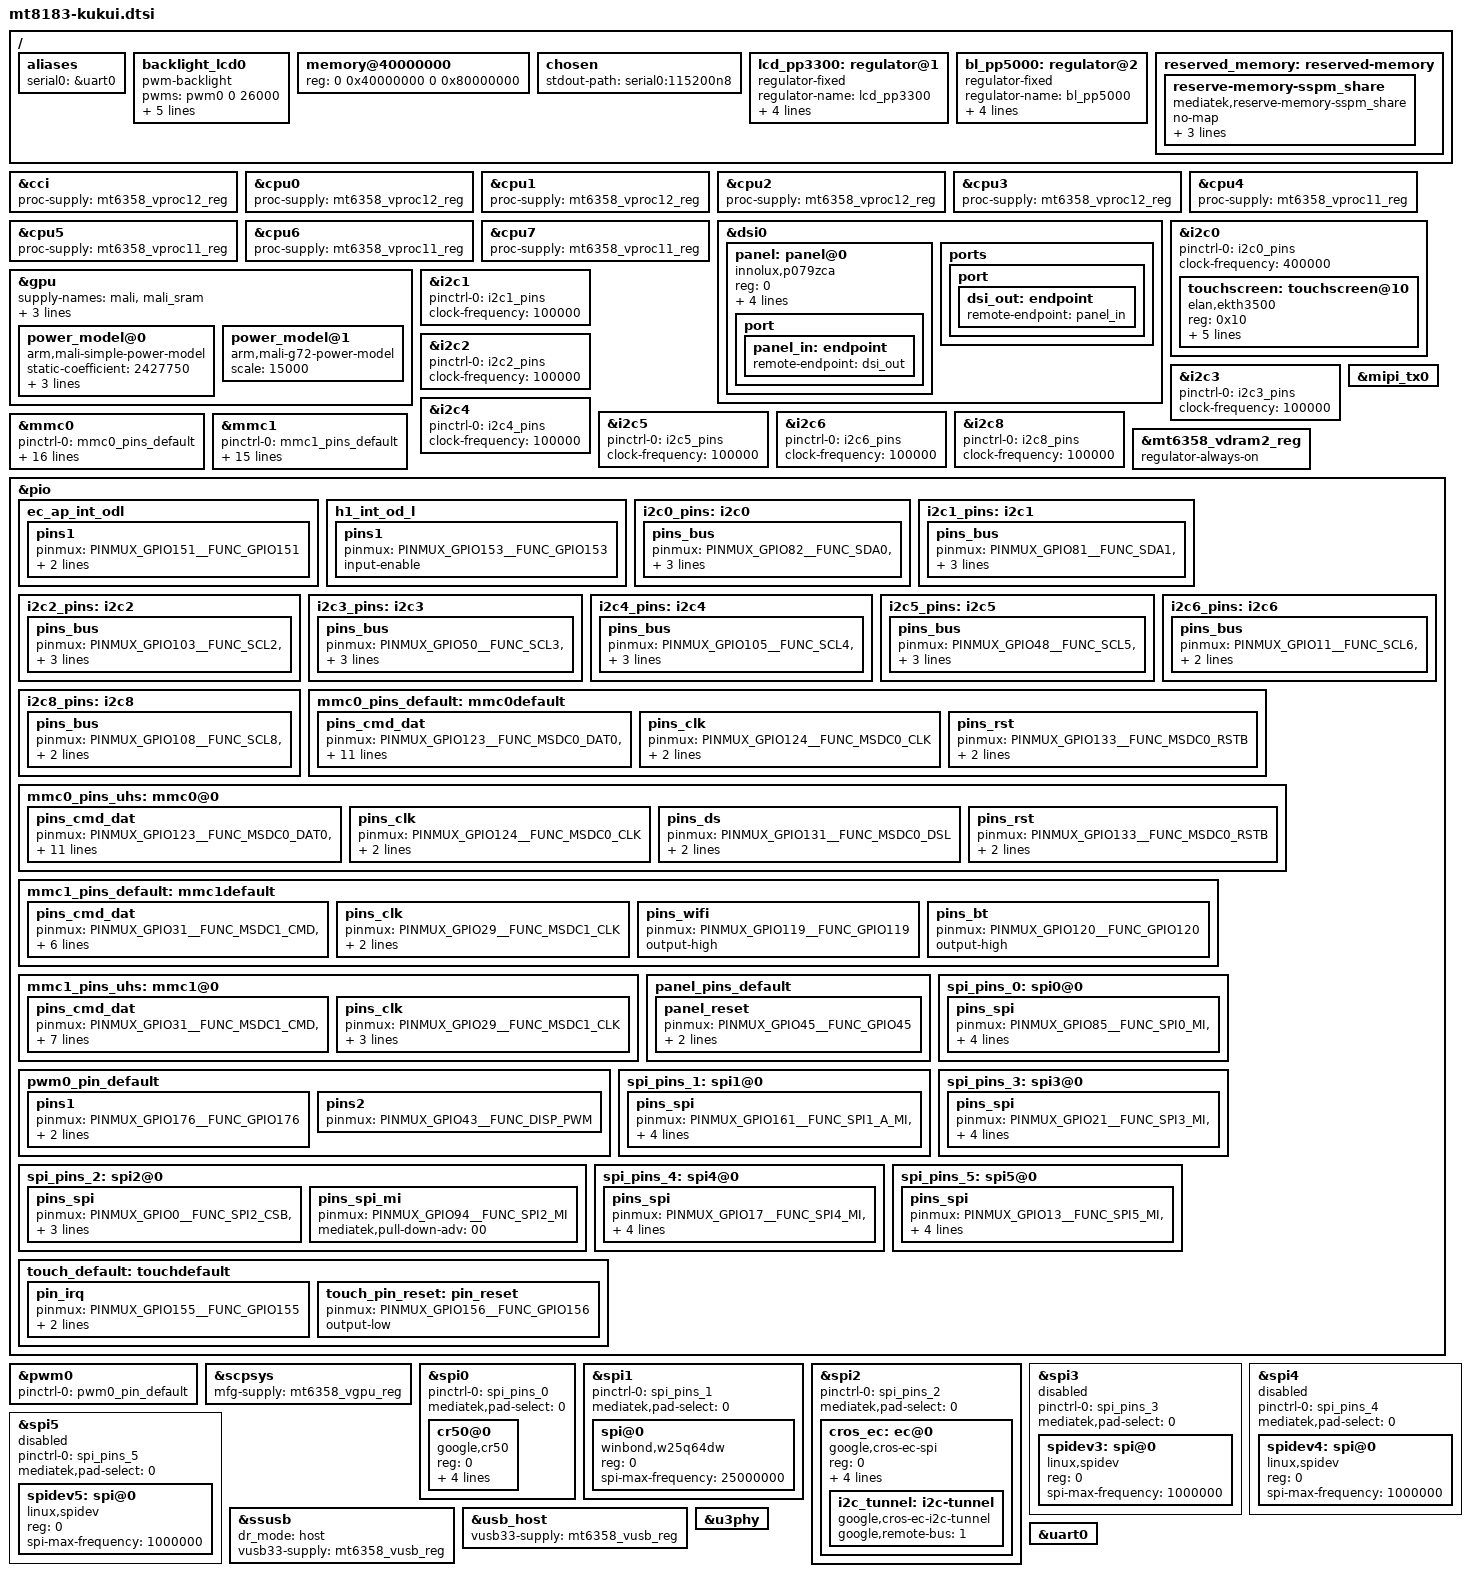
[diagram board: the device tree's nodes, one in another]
// SPDX-License-Identifier: (GPL-2.0 OR MIT)
/*
 * Copyright (c) 2018 MediaTek Inc.
 * Author: Ben Ho <ben.ho@mediatek.com>
 *	   Erin Lo <erin.lo@mediatek.com>
 */

#include <dt-bindings/gpio/gpio.h>
#include "mt8183.dtsi"
#include "mt6358.dtsi"

/ {
	aliases {
		serial0 = &uart0;
	};

	backlight_lcd0: backlight_lcd0 {
		compatible = "pwm-backlight";
		pwms = <&pwm0 0 26000>;
		power-supply = <&bl_pp5000>;
		enable-gpios = <&pio 176 0>;
		brightness-levels = <
			0 64 128 192 256 320 384 448
			512 576 640 704 768 832 896 960
			1023>;
		default-brightness-level = <9>;
		status = "okay";
	};

	memory@40000000 {
		device_type = "memory";
		reg = <0 0x40000000 0 0x80000000>;
	};

	chosen {
		stdout-path = "serial0:115200n8";
	};

	lcd_pp3300: regulator@1 {
		compatible = "regulator-fixed";
		regulator-name = "lcd_pp3300";
		regulator-min-microvolt = <3300000>;
		regulator-max-microvolt = <3300000>;
		regulator-always-on;
		regulator-boot-on;
	};

	bl_pp5000: regulator@2 {
		compatible = "regulator-fixed";
		regulator-name = "bl_pp5000";
		regulator-min-microvolt = <5000000>;
		regulator-max-microvolt = <5000000>;
		regulator-always-on;
		regulator-boot-on;
	};

	reserved_memory: reserved-memory {
		#address-cells = <2>;
		#size-cells = <2>;
		ranges;

		reserve-memory-sspm_share {
			compatible = "mediatek,reserve-memory-sspm_share";
			no-map;
			status = "okay";
			size = <0 0x110000>; /* 1M + 64K */
			alignment = <0 0x10000>;
			alloc-ranges = <0 0x40000000 0 0x60000000>;
		};
	};
};

&cci {
	proc-supply = <&mt6358_vproc12_reg>;
};

&cpu0 {
	proc-supply = <&mt6358_vproc12_reg>;
};

&cpu1 {
	proc-supply = <&mt6358_vproc12_reg>;
};

&cpu2 {
	proc-supply = <&mt6358_vproc12_reg>;
};

&cpu3 {
	proc-supply = <&mt6358_vproc12_reg>;
};

&cpu4 {
	proc-supply = <&mt6358_vproc11_reg>;
};

&cpu5 {
	proc-supply = <&mt6358_vproc11_reg>;
};

&cpu6 {
	proc-supply = <&mt6358_vproc11_reg>;
};

&cpu7 {
	proc-supply = <&mt6358_vproc11_reg>;
};

&dsi0 {
	status = "okay";
	#address-cells = <1>;
	#size-cells = <0>;
	panel: panel@0 {
		compatible = "innolux,p079zca";
		reg = <0>;
		enable-gpios = <&pio 45 0>;
		pinctrl-names = "default";
		pinctrl-0 = <&panel_pins_default>;
		power-supply = <&lcd_pp3300>;
		backlight = <&backlight_lcd0>;
		status = "okay";
		port {
			panel_in: endpoint {
				remote-endpoint = <&dsi_out>;
			};
		};
	};

	ports {
		port {
			dsi_out: endpoint {
				remote-endpoint = <&panel_in>;
			};
		};
	};
};

&gpu {
	supply-names = "mali","mali_sram";
	mali-supply = <&mt6358_vgpu_reg>;
	mali_sram-supply = <&mt6358_vsram_gpu_reg>;
	operating-points-v2 = <&gpu_opp_table>;
	power_model@0 {
		compatible = "arm,mali-simple-power-model";
		static-coefficient = <2427750>;
		dynamic-coefficient = <4687>;
		ts = <20000 2000 (-20) 2>;
		thermal-zone = "cpu_thermal";
	};
	power_model@1 {
		compatible = "arm,mali-g72-power-model";
		scale = <15000>;
	};
};

&i2c0 {
	pinctrl-names = "default";
	pinctrl-0 = <&i2c0_pins>;
	status = "okay";
	clock-frequency = <400000>;
	#address-cells = <1>;
	#size-cells = <0>;

	touchscreen: touchscreen@10 {
		compatible = "elan,ekth3500";
		reg = <0x10>;
		interrupt-parent = <&pio>;
		interrupts = <155 IRQ_TYPE_LEVEL_LOW>;
		int-gpio = <&pio 155 0>;
		pinctrl-names = "default";
		pinctrl-0 = <&touch_default>;

		reset-gpios = <&pio 156 1>;
	};
};

&i2c1 {
	pinctrl-names = "default";
	pinctrl-0 = <&i2c1_pins>;
	status = "okay";
	clock-frequency = <100000>;
};

&i2c2 {
	pinctrl-names = "default";
	pinctrl-0 = <&i2c2_pins>;
	status = "okay";
	clock-frequency = <100000>;
};

&i2c3 {
	pinctrl-names = "default";
	pinctrl-0 = <&i2c3_pins>;
	status = "okay";
	clock-frequency = <100000>;
};

&i2c4 {
	pinctrl-names = "default";
	pinctrl-0 = <&i2c4_pins>;
	status = "okay";
	clock-frequency = <100000>;
};

&i2c5 {
	pinctrl-names = "default";
	pinctrl-0 = <&i2c5_pins>;
	status = "okay";
	clock-frequency = <100000>;
};

&i2c6 {
	pinctrl-names = "default";
	pinctrl-0 = <&i2c6_pins>;
	status = "okay";
	clock-frequency = <100000>;
};

&i2c8 {
	pinctrl-names = "default";
	pinctrl-0 = <&i2c8_pins>;
	status = "okay";
	clock-frequency = <100000>;
};

&mipi_tx0 {
	status = "okay";
};

&mmc0 {
	status = "okay";
	pinctrl-names = "default", "state_uhs";
	pinctrl-0 = <&mmc0_pins_default>;
	pinctrl-1 = <&mmc0_pins_uhs>;
	bus-width = <8>;
	max-frequency = <200000000>;
	cap-mmc-highspeed;
	mmc-hs200-1_8v;
	mmc-hs400-1_8v;
	cap-mmc-hw-reset;
	no-sdio;
	no-sd;
	hs400-ds-delay = <0x13813>;
	vmmc-supply = <&mt6358_vemc_reg>;
	vqmmc-supply = <&mt6358_vio18_reg>;
	assigned-clocks = <&topckgen CLK_TOP_MUX_MSDC50_0>;
	assigned-clock-parents = <&topckgen CLK_TOP_MSDCPLL_CK>;
	non-removable;
};

&mmc1 {
	status = "okay";
	pinctrl-names = "default", "state_uhs";
	pinctrl-0 = <&mmc1_pins_default>;
	pinctrl-1 = <&mmc1_pins_uhs>;
	vmmc-supply = <&mt6358_vmch_reg>;
	vqmmc-supply = <&mt6358_vmc_reg>;
	bus-width = <4>;
	max-frequency = <200000000>;
	drv-type = <2>;
	cap-sd-highspeed;
	sd-uhs-sdr50;
	sd-uhs-sdr104;
	keep-power-in-suspend;
	enable-sdio-wakeup;
	cap-sdio-irq;
	non-removable;
	no-mmc;
	no-sd;
};

&mt6358_vdram2_reg {
	regulator-always-on;
};

&pio {
	ec_ap_int_odl: ec_ap_int_odl {
		pins1 {
			pinmux = <PINMUX_GPIO151__FUNC_GPIO151>;
			input-enable;
			bias-pull-up;
		};
	};

	h1_int_od_l: h1_int_od_l {
		pins1 {
			pinmux = <PINMUX_GPIO153__FUNC_GPIO153>;
			input-enable;
		};
	};

	i2c0_pins: i2c0 {
		pins_bus {
			pinmux = <PINMUX_GPIO82__FUNC_SDA0>,
				 <PINMUX_GPIO83__FUNC_SCL0>;
			mediatek,pull-up-adv = <3>;
			mediatek,drive-strength-adv = <00>;
		};
	};

	i2c1_pins: i2c1 {
		pins_bus {
			pinmux = <PINMUX_GPIO81__FUNC_SDA1>,
				 <PINMUX_GPIO84__FUNC_SCL1>;
			mediatek,pull-up-adv = <3>;
			mediatek,drive-strength-adv = <00>;
		};
	};

	i2c2_pins: i2c2 {
		pins_bus {
			pinmux = <PINMUX_GPIO103__FUNC_SCL2>,
				 <PINMUX_GPIO104__FUNC_SDA2>;
			bias-disable;
			mediatek,drive-strength-adv = <00>;
		};
	};

	i2c3_pins: i2c3 {
		pins_bus {
			pinmux = <PINMUX_GPIO50__FUNC_SCL3>,
				 <PINMUX_GPIO51__FUNC_SDA3>;
			mediatek,pull-up-adv = <3>;
			mediatek,drive-strength-adv = <00>;
		};
	};

	i2c4_pins: i2c4 {
		pins_bus {
			pinmux = <PINMUX_GPIO105__FUNC_SCL4>,
				 <PINMUX_GPIO106__FUNC_SDA4>;
			bias-disable;
			mediatek,drive-strength-adv = <00>;
		};
	};

	i2c5_pins: i2c5 {
		pins_bus {
			pinmux = <PINMUX_GPIO48__FUNC_SCL5>,
				 <PINMUX_GPIO49__FUNC_SDA5>;
			mediatek,pull-up-adv = <3>;
			mediatek,drive-strength-adv = <00>;
		};
	};

	i2c6_pins: i2c6 {
		pins_bus {
			pinmux = <PINMUX_GPIO11__FUNC_SCL6>,
				 <PINMUX_GPIO12__FUNC_SDA6>;
			bias-disable;
		};
	};

	i2c8_pins: i2c8 {
		pins_bus {
			pinmux = <PINMUX_GPIO108__FUNC_SCL8>,
				 <PINMUX_GPIO109__FUNC_SDA8>;
			bias-disable;
		};
	};

	mmc0_pins_default: mmc0default {
		pins_cmd_dat {
			pinmux = <PINMUX_GPIO123__FUNC_MSDC0_DAT0>,
				 <PINMUX_GPIO128__FUNC_MSDC0_DAT1>,
				 <PINMUX_GPIO125__FUNC_MSDC0_DAT2>,
				 <PINMUX_GPIO132__FUNC_MSDC0_DAT3>,
				 <PINMUX_GPIO126__FUNC_MSDC0_DAT4>,
				 <PINMUX_GPIO129__FUNC_MSDC0_DAT5>,
				 <PINMUX_GPIO127__FUNC_MSDC0_DAT6>,
				 <PINMUX_GPIO130__FUNC_MSDC0_DAT7>,
				 <PINMUX_GPIO122__FUNC_MSDC0_CMD>;
			input-enable;
			drive-strength = <MTK_DRIVE_14mA>;
			mediatek,pull-up-adv = <01>;
		};

		pins_clk {
			pinmux = <PINMUX_GPIO124__FUNC_MSDC0_CLK>;
			drive-strength = <MTK_DRIVE_14mA>;
			mediatek,pull-down-adv = <10>;
		};

		pins_rst {
			pinmux = <PINMUX_GPIO133__FUNC_MSDC0_RSTB>;
			drive-strength = <MTK_DRIVE_14mA>;
			mediatek,pull-down-adv = <01>;
		};
	};

	mmc0_pins_uhs: mmc0@0 {
		pins_cmd_dat {
			pinmux = <PINMUX_GPIO123__FUNC_MSDC0_DAT0>,
				 <PINMUX_GPIO128__FUNC_MSDC0_DAT1>,
				 <PINMUX_GPIO125__FUNC_MSDC0_DAT2>,
				 <PINMUX_GPIO132__FUNC_MSDC0_DAT3>,
				 <PINMUX_GPIO126__FUNC_MSDC0_DAT4>,
				 <PINMUX_GPIO129__FUNC_MSDC0_DAT5>,
				 <PINMUX_GPIO127__FUNC_MSDC0_DAT6>,
				 <PINMUX_GPIO130__FUNC_MSDC0_DAT7>,
				 <PINMUX_GPIO122__FUNC_MSDC0_CMD>;
			input-enable;
			drive-strength = <MTK_DRIVE_14mA>;
			mediatek,pull-up-adv = <01>;
		};

		pins_clk {
			pinmux = <PINMUX_GPIO124__FUNC_MSDC0_CLK>;
			drive-strength = <MTK_DRIVE_14mA>;
			mediatek,pull-down-adv = <10>;
		};

		pins_ds {
			pinmux = <PINMUX_GPIO131__FUNC_MSDC0_DSL>;
			drive-strength = <MTK_DRIVE_14mA>;
			mediatek,pull-down-adv = <10>;
		};

		pins_rst {
			pinmux = <PINMUX_GPIO133__FUNC_MSDC0_RSTB>;
			drive-strength = <MTK_DRIVE_14mA>;
			mediatek,pull-up-adv = <01>;
		};
	};

	mmc1_pins_default: mmc1default {
		pins_cmd_dat {
			pinmux = <PINMUX_GPIO31__FUNC_MSDC1_CMD>,
				 <PINMUX_GPIO32__FUNC_MSDC1_DAT0>,
				 <PINMUX_GPIO34__FUNC_MSDC1_DAT1>,
				 <PINMUX_GPIO33__FUNC_MSDC1_DAT2>,
				 <PINMUX_GPIO30__FUNC_MSDC1_DAT3>;
			input-enable;
			mediatek,pull-up-adv = <10>;
		};

		pins_clk {
			pinmux = <PINMUX_GPIO29__FUNC_MSDC1_CLK>;
			input-enable;
			mediatek,pull-down-adv = <10>;
		};

		pins_wifi {
			pinmux = <PINMUX_GPIO119__FUNC_GPIO119>;
			output-high;
		};

		pins_bt {
			pinmux = <PINMUX_GPIO120__FUNC_GPIO120>;
			output-high;
		};
	};

	mmc1_pins_uhs: mmc1@0 {
		pins_cmd_dat {
			pinmux = <PINMUX_GPIO31__FUNC_MSDC1_CMD>,
				 <PINMUX_GPIO32__FUNC_MSDC1_DAT0>,
				 <PINMUX_GPIO34__FUNC_MSDC1_DAT1>,
				 <PINMUX_GPIO33__FUNC_MSDC1_DAT2>,
				 <PINMUX_GPIO30__FUNC_MSDC1_DAT3>;
			drive-strength = <MTK_DRIVE_6mA>;
			input-enable;
			mediatek,pull-up-adv = <10>;
		};

		pins_clk {
			pinmux = <PINMUX_GPIO29__FUNC_MSDC1_CLK>;
			drive-strength = <MTK_DRIVE_8mA>;
			mediatek,pull-down-adv = <10>;
			input-enable;
		};
	};

	panel_pins_default: panel_pins_default {
		panel_reset {
			pinmux = <PINMUX_GPIO45__FUNC_GPIO45>;
			output-low;
			bias-pull-up;
		};
	};

	pwm0_pin_default: pwm0_pin_default {
		pins1 {
			pinmux = <PINMUX_GPIO176__FUNC_GPIO176>;
			output-high;
			bias-pull-up;
		};
		pins2 {
			pinmux = <PINMUX_GPIO43__FUNC_DISP_PWM>;
		};
	};

	spi_pins_0: spi0@0 {
		pins_spi{
			pinmux = <PINMUX_GPIO85__FUNC_SPI0_MI>,
				 <PINMUX_GPIO86__FUNC_SPI0_CSB>,
				 <PINMUX_GPIO87__FUNC_SPI0_MO>,
				 <PINMUX_GPIO88__FUNC_SPI0_CLK>;
			bias-disable;
		};
	};

	spi_pins_1: spi1@0 {
		pins_spi{
			pinmux = <PINMUX_GPIO161__FUNC_SPI1_A_MI>,
				 <PINMUX_GPIO162__FUNC_SPI1_A_CSB>,
				 <PINMUX_GPIO163__FUNC_SPI1_A_MO>,
				 <PINMUX_GPIO164__FUNC_SPI1_A_CLK>;
			bias-disable;
		};
	};

	spi_pins_2: spi2@0 {
		pins_spi{
			pinmux = <PINMUX_GPIO0__FUNC_SPI2_CSB>,
				 <PINMUX_GPIO1__FUNC_SPI2_MO>,
				 <PINMUX_GPIO2__FUNC_SPI2_CLK>;
			bias-disable;
		};
		pins_spi_mi {
			pinmux = <PINMUX_GPIO94__FUNC_SPI2_MI>;
			mediatek,pull-down-adv = <00>;
		};
	};

	spi_pins_3: spi3@0 {
		pins_spi{
			pinmux = <PINMUX_GPIO21__FUNC_SPI3_MI>,
				 <PINMUX_GPIO22__FUNC_SPI3_CSB>,
				 <PINMUX_GPIO23__FUNC_SPI3_MO>,
				 <PINMUX_GPIO24__FUNC_SPI3_CLK>;
			bias-disable;
		};
	};

	spi_pins_4: spi4@0 {
		pins_spi{
			pinmux = <PINMUX_GPIO17__FUNC_SPI4_MI>,
				 <PINMUX_GPIO18__FUNC_SPI4_CSB>,
				 <PINMUX_GPIO19__FUNC_SPI4_MO>,
				 <PINMUX_GPIO20__FUNC_SPI4_CLK>;
			bias-disable;
		};
	};

	spi_pins_5: spi5@0 {
		pins_spi{
			pinmux = <PINMUX_GPIO13__FUNC_SPI5_MI>,
				 <PINMUX_GPIO14__FUNC_SPI5_CSB>,
				 <PINMUX_GPIO15__FUNC_SPI5_MO>,
				 <PINMUX_GPIO16__FUNC_SPI5_CLK>;
			bias-disable;
		};
	};

	touch_default: touchdefault {
		pin_irq {
			pinmux = <PINMUX_GPIO155__FUNC_GPIO155>;
			input-enable;
			bias-pull-up;
		};

		touch_pin_reset: pin_reset {
			pinmux = <PINMUX_GPIO156__FUNC_GPIO156>;
			output-low;
		};
	};
};

&pwm0 {
	status = "okay";
	pinctrl-names = "default";
	pinctrl-0 = <&pwm0_pin_default>;
};

&scpsys {
	mfg-supply = <&mt6358_vgpu_reg>;
};

&spi0 {
	pinctrl-names = "default";
	pinctrl-0 = <&spi_pins_0>;
	mediatek,pad-select = <0>;
	status = "okay";

	cr50@0 {
		compatible = "google,cr50";
		reg = <0>;
		spi-max-frequency = <1000000>;
		pinctrl-names = "default";
		pinctrl-0 = <&h1_int_od_l>;
		interrupt-parent = <&pio>;
		interrupts = <153 IRQ_TYPE_EDGE_RISING>;
	};
};

&spi1 {
	pinctrl-names = "default";
	pinctrl-0 = <&spi_pins_1>;
	mediatek,pad-select = <0>;
	status = "okay";

	spi@0 {
		compatible = "winbond,w25q64dw", "jedec,spi-nor";
		reg = <0>;
		spi-max-frequency = <25000000>;
	};
};

&spi2 {
	pinctrl-names = "default";
	pinctrl-0 = <&spi_pins_2>;
	mediatek,pad-select = <0>;
	status = "okay";

	cros_ec: ec@0 {
		compatible = "google,cros-ec-spi";
		reg = <0>;
		spi-max-frequency = <3000000>;
		interrupt-parent = <&pio>;
		interrupts = <151 IRQ_TYPE_LEVEL_LOW>;
		pinctrl-names = "default";
		pinctrl-0 = <&ec_ap_int_odl>;

		i2c_tunnel: i2c-tunnel {
			compatible = "google,cros-ec-i2c-tunnel";
			google,remote-bus = <1>;
			#address-cells = <1>;
			#size-cells = <0>;
		};
	};
};

&spi3 {
	pinctrl-names = "default";
	pinctrl-0 = <&spi_pins_3>;
	mediatek,pad-select = <0>;
	status = "disabled";

	spidev3: spi@0 {
		compatible = "linux,spidev";
		reg = <0>;
		spi-max-frequency = <1000000>;
	};
};

&spi4 {
	pinctrl-names = "default";
	pinctrl-0 = <&spi_pins_4>;
	mediatek,pad-select = <0>;
	status = "disabled";

	spidev4: spi@0 {
		compatible = "linux,spidev";
		reg = <0>;
		spi-max-frequency = <1000000>;
	};
};

&spi5 {
	pinctrl-names = "default";
	pinctrl-0 = <&spi_pins_5>;
	mediatek,pad-select = <0>;
	status = "disabled";

	spidev5: spi@0 {
		compatible = "linux,spidev";
		reg = <0>;
		spi-max-frequency = <1000000>;
	};
};

&ssusb {
	dr_mode = "host";
	vusb33-supply = <&mt6358_vusb_reg>;
	status = "okay";
};

&usb_host {
	vusb33-supply = <&mt6358_vusb_reg>;
	status = "okay";
};

&u3phy {
	status = "okay";
};

&uart0 {
	status = "okay";
};

#include <arm/cros-ec-keyboard.dtsi>
#include <arm/cros-ec-sbs.dtsi>

